# STM32MP25_CM33 register map
File version: 1.3
CPU: CM33 r0p1, little endian, MPU, FPU, vendor SysTick, 8 interrupt priority bits
Registers are 32-bit, read-write, reset 0x0 unless marked. A register's access mark holds for its fields unless they carry their own. Offsets are from the block's base; [hi:lo] are bit positions; {n}, {i} and the like mark numbered series.

## CRYP1 — CRYP address block description
Base 0x42030000
Same registers: CRYP2 0x42040000, CRYP1_S 0x52030000, CRYP2_S 0x52040000
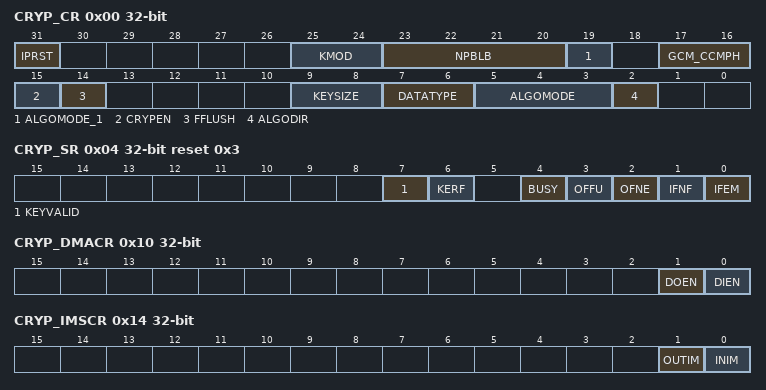
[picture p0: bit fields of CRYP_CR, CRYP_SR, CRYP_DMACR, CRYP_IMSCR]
0x00 CRYP_CR — CRYP control register
  [31] IPRST — CRYP peripheral software reset Setting the bit resets the CRYP peripheral, putting all registers to their default values, except the IPRST bit itself. This bit must be kept cleared while writing any configuration registers.
  [25:24] KMOD — Key mode selection This bit field defines how the CRYP key can be used by the application. KEYSIZE must be correctly initialized when setting KMOD[1:0] different from zero. Others: Reserved Shared-key mode can only be used in AES mode. Attempts to write the bit field are ignored when BUSY is set.
    0=Normal-key mode. Key registers are freely usable.; 2=Shared-key mode. If shared-key mode is properly initialized in SAES peripheral, the CRYP peripheral automatically loads its key registers with the data stored in the SAES key registers. The key value is available in CRYP key registers when BUSY bit is cleared and KEYVALID is set in the CRYP_SR register. Key error flag KERF is set otherwise in the CRYP_SR register.
  [23:20] NPBLB — Number of padding bytes in last block This padding information must be filled by software before processing the last block of GCM payload encryption or CCM payload decryption, otherwise authentication tag computation is incorrect. ... Attempts to write the bit field are ignored when BUSY is set.
    0=All bytes are valid (no padding); 1=Padding for the last LSB byte; 15=Padding for the 15 LSB bytes of last block
  [19] ALGOMODE_1 — ALGOMODE[3]
  [17:16] GCM_CCMPH — GCM or CCM phase selection This bit field selects the phase, applicable only with GCM, GMAC or CCM chaining modes. Attempts to write the bit field are ignored when BUSY is set.
    0=Initialization phase; 1=Header phase; 2=Payload phase; 3=Final phase
  [15] CRYPEN — CRYP enable This bit enables/disables the CRYP peripheral. This bit is automatically cleared by hardware upon the completion of the key preparation (ALGOMODE[3:0] at 0x7) and upon the completion of GCM/GMAC/CCM initialization phase. The bit cannot be set as long as KEYVALID is cleared.
    0=CRYP disabled; 1=CRYP enabled
  [14] FFLUSH — FIFO flush This bit enables/disables the flushing of CRYP input and output FIFOs. Reading this bit always returns 0. When CRYPEN is cleared, writing this bit to 1 flushes both input and output FIFOs (that is read and write pointers of the FIFOs are reset). FFLUSH bit must be set when BUSY is cleared, otherwise the FIFO is flushed, but the block being processed may be pushed into the output FIFO just after the flush operation, resulting in a non-empty FIFO condition. Attempts to write FFLUSH are ignored when CRYPEN is set.
    0=No effect; 1=FIFO flush enabled
  [9:8] KEYSIZE — Key size selection This bit field defines the key length in bits of the key used by CRYP in AES mode (that is, it has no effect in the DES or TDES modes). When KEYSIZE is changed, KEYVALID bit is cleared. Attempts to write the bit field are ignored when BUSY is set.
    0=128-bits; 1=192 bits; 2=256 bits
  [7:6] DATATYPE — Data type This bit field defines the format of data written in the CRYP_DINR register or read from the CRYP_DOUTR register, through selecting the mode of data swapping. This swapping is defined in Section59.4.16: CRYP data registers and data swapping. Attempts to write the bit field are ignored when BUSY is set.
    0=No swapping (32-bit data); 1=Half-word swapping (16-bit data); 2=Byte swapping (8-bit data); 3=Bit-level swapping
  [5:3] ALGOMODE — ALGOMODE[2:0]: Algorithm mode This bit field selects the algorithm/chaining mode. Others: Reserved Changing ALGOMODE[3:0] from AES algorithm to DES or TDES (or the reverse) clears KEYVALID. KEYVALID is not cleared when the algorithm type is kept between two ALGOMODE[3:0], that is between TDES-ECB and TDES-CBC or between AES-ECB and AES_CTR. Attempts to write the bit field are ignored when BUSY is set.
    0=TDES-ECB (triple-DES Electronic Codebook); 1=TDES-CBC (triple-DES Cipher Block Chaining); 2=DES-ECB (simple DES Electronic Codebook); 3=DES-CBC (simple DES Cipher Block Chaining); 4=AES electronic codebook (AES-ECB); 5=AES cipher Block Chaining (AES-CBC); 6=AES counter mode (AES-CTR); 7=AES key preparation for ECB or CBC decryption
  [2] ALGODIR — Algorithm direction This bit selects the algorithm direction. Attempts to write the bit field are ignored when BUSY is set.
    0=Encryption; 1=Decryption
0x04 CRYP_SR ro reset 0x3 — CRYP status register
  [7] KEYVALID — Key valid flag This read-only bit is set by hardware when the key of size defined by KEYSIZE is loaded in CRYP_KxR/LR key registers. It is valid for both AES and DES/TDES algorithms. The CRYPEN bit can only be set when KEYVALID is set. In normal mode when KMOD[1:0] is at zero, the key must be written in the key registers in the correct sequence, otherwise the KERF flag is set and KEYVALID remains cleared. When KMOD[1:0] is different from zero, the BUSY flag is automatically set by CRYP. When the key is loaded successfully, BUSY is cleared and KEYVALID set. Upon an error, KERF is set, BUSY cleared and KEYVALID remains cleared. If set, KERF must be cleared, otherwise KEYVALID cannot be set. For further information on key loading, refer to Section59.4.17: CRYP key registers.
    0=Key not valid; 1=Key valid
  [6] KERF — Key error flag This read-only bit is set by hardware when key information failed to load into key registers. KERF is triggered upon any of the following errors: CRYP_KxR/LR register write does not respect the correct order (refer to Section59.4.17: CRYP key registers for details). CRYP fails to load the AES key shared by SAES peripheral (KMOD=0x2). Application wrote KMOD=0x2 with ALGOMODE[3:0] selecting either DES or TDES algorithm. KERF must be cleared by the application software, otherwise KEYVALID cannot be set. It can be done through IPRST bit of CRYP_CR, or when a correct key writing sequence starts.
    0=No key error detected; 1=Key information failed to load into key registers
  [4] BUSY — Busy bit This flag indicates whether CRYP is idle or busy. CRYP is flagged as idle when disabled (CRYPEN=0) or when the AES or DES core is not processing any data. It happens when the last processing has completed, or CRYP is waiting for enough data in the input FIFO or enough free space in the output FIFO (that is in each case at least 2 words in the DES, 4 words in the AES). CRYP is flagged as busy when processing a block data, preparing a key (AES ECB or CBC decryption only), or transferring a shared key from SAES peripheral.
    0=Idle; 1=Busy
  [3] OFFU — Output FIFO full flag
    0=Output FIFO is not full; 1=Output FIFO is full
  [2] OFNE — Output FIFO not empty flag
    0=Output FIFO is empty; 1=Output FIFO is not empty
  [1] IFNF — Input FIFO not full flag
    0=Input FIFO is full; 1=Input FIFO is not full
  [0] IFEM — Input FIFO empty flag
    0=Input FIFO is not empty; 1=Input FIFO is empty
0x08 CRYP_DINR — CRYP data input register
  [31:0] DIN — Data input In AES mode four-fold sequential write to this bit field during the Input phase results in pushing a complete 16-byte block into the CRYP input FIFO. From the first to the fourth write, the corresponding data weights are [127:96], [95:64], [63:32], and [31:0]. In DES/TDES mode a two-fold sequential write to this bit field during the Input phase results in pushing a complete 8-bytes block into the CRYP input FIFO. From the first to the second write, the corresponding data weights are [63:32] then [31:0]. Input FIFO can receive up to two 16-byte blocks of plaintext (when encrypting) or ciphertext (when decrypting) in AES mode. In DES/TDES mode it is up to four 8-byte blocks. If EN bit is set in CRYP_CR register, when at least four 32-bit words have been pushed into the input FIFO (two in DES/TDES mode), and when at least four 32-bit words are free in the output FIFO (two in DES/TDES mode), the CRYP automatically starts an encryption or decryption process, setting the BUSY bit. Reading this register pops data off the input FIFO (oldest value is returned). The data present in the input FIFO are returned only if CRYPENis cleared (undefined value is returned otherwise). Following one or more reads the FIFO must be flushed (setting the FFLUSH bit) prior to processing new data.
0x0C CRYP_DOUTR ro — CRYP data output register
  [31:0] DOUT — Data output In AES mode four-fold sequential read to this bit field during the output phase results in retrieving a complete 16-byte block from the CRYP output FIFO. From the first to the fourth read, the corresponding data weights are [127:96], [95:64], [63:32], and [31:0]. In DES/TDES mode a two-fold sequential read to this bit field during the output phase results in retrieving a complete 8-byte block from the CRYP input FIFO. From the first to the second read, the corresponding data weights are [63:32] then [31:0]. Output FIFO can store up to two 16-byte blocks of plaintext (when decrypting) or ciphertext (when encrypting) in AES mode. In DES/TDES mode it is up to four 8-byte blocks. When the output FIFO is empty a read returns an undefined value. Writes are ignored.
0x10 CRYP_DMACR — CRYP DMA control register
  [1] DOEN — DMA output enable When this bit is set, DMA requests are automatically generated by the peripheral during the output data phase.
    0=Outgoing data transfer from CRYP via DMA is disabled; 1=Outgoing data transfer from CRYP via DMA is enabled
  [0] DIEN — DMA input enable When this bit is set, DMA requests are automatically generated by the peripheral during the input data phase.
    0=Incoming data transfer to CRYP via DMA is disabled; 1=Incoming data transfer to CRYP via DMA is enabled
0x14 CRYP_IMSCR — CRYP interrupt mask set/clear register
  [1] OUTIM — Output FIFO service interrupt mask This bit enables or disables (masks) the CRYP output FIFO service interrupt generation when OUTRIS is set.
    0=Output FIFO interrupt is disabled (masked), masked interrupt status (OUTMIS) stays cleared; 1=Output FIFO interrupt is enabled (not masked)
  [0] INIM — Input FIFO service interrupt mask This bit enables or disables (masks) the CRYP input FIFO service interrupt generation when INRIS is set.
    0=Input FIFO interrupt is disabled (masked), masked interrupt status (INMIS) stays cleared; 1=Input FIFO interrupt is enabled (not masked)
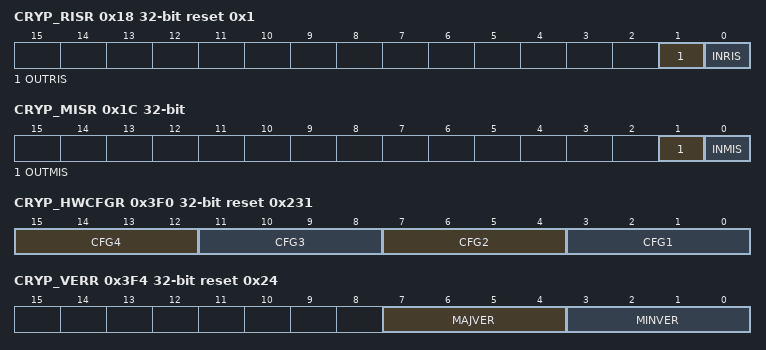
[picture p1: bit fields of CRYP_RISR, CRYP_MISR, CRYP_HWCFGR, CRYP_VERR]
0x18 CRYP_RISR ro reset 0x1 — CRYP raw interrupt status register
  [1] OUTRIS — Output FIFO service raw interrupt status This read-only bit is set by hardware when an output FIFO flag (OFFU or OFNE) is set in CRYP_SR register, regardless of the OUTIM mask bit value in CRYP_IMSCR register.
    0=No output FIFO event detected; 1=Output FIFO full or not empty detected; an interrupt is generated if OUTIM bit is set in CRYP_IMSCR register
  [0] INRIS — Input FIFO service raw interrupt status This read-only bit is set by hardware when an input FIFO flag (IFNF or IFEM) is set in CRYP_SR register, regardless of the INIM mask bit value in CRYP_IMSCR register.
    0=No input FIFO event detected; 1=Input FIFO empty or not full detected; an interrupt is generated if CRYPEN is set and if INIM bit is set in CRYP_IMSCR register
0x1C CRYP_MISR ro — CRYP masked interrupt status register
  [1] OUTMIS — Output FIFO service masked interrupt status This read-only bit is set by hardware when an output FIFO flag (OFFU or OFNE) is set in CRYP_SR register. If the OUTIM mask bit is cleared in CRYP_IMSCR register, the OUTMIS bit stays cleared (masked). The OUTMIS bit is cleared by reading data from the output FIFO until OFNE flag is cleared (output FIFO empty). It is not cleared by disabling CRYP with CRYPEN bit.
    0=No output FIFO event detected or OUTIM mask cleared in CRYP_IMSCR; 1=Output FIFO full or not empty detected, with an interrupt pending
  [0] INMIS — Input FIFO service masked interrupt status This read-only bit is set by hardware when an input FIFO flag (IFNF or IFEM) is set in CRYP_SR register. If the INIM mask bit is cleared in CRYP_IMSCR register, the INMIS bit stays cleared (masked). The INMIS bit is cleared by writing data to the input FIFO until IFEM flag is cleared (there is at least one word in input FIFO), or by clearing CRYPEN, When CRYP is disabled, INMIS bit stays low even if the input FIFO is empty.
    0=No input FIFO event detected or INIM mask cleared in CRYP_IMSCR or CRYPEN bit cleared; 1=Input FIFO empty or not full detected, with an interrupt pending
0x20 CRYP_K0LR wo — CRYP key register 0L
  [31:0] K — Key bit x (x= 255 to 224) This write-only bit field contains the bits [255:224] of the AES encryption or decryption key, depending on the operating mode. This register is not used in DES/TDES mode. Write to CRYP_KxR/LR registers is ignored when CRYP is busy (BUSY bit set). When key is coming from the SAES peripheral (KMOD[1:0]=0x2) in AES mode, write is also ignored. With KMOD[1:0] at 0x0, a special writing sequence is required. In this sequence, any valid write to CRYP_KxR/LR register clears the KEYVALID flag except for the sequence-completing write that sets it. Also refer to the description of the KEYVALID flag in the CRYP_SR register.
0x24 CRYP_K0RR wo — CRYP key register 0R
  [31:0] K — Key bit x (x= 223 to 192) This write-only bit field contains the bits [223:192] of the AES encryption or decryption key, depending on the operating mode. This register is not used in DES/TDES mode. Refer to the CRYP_K0LR register for information relative to writing CRYP_KxR/LR registers.
0x28 CRYP_K1LR wo — CRYP key register 1L
  [31:0] K — Key bit x (x= 191 to 160) This write-only bit field contains the bits [191:160] of the AES encryption or decryption key, depending on the operating mode. In DES/TDES mode this bit field contains the bits [64:33] of the key K1, with parity bits unused. Refer to the CRYP_K0LR register for information relative to writing CRYP_KxR/LR registers.
0x2C CRYP_K1RR wo — CRYP key register 1R
  [31:0] K — Key bit x (x= 159 to 128) This write-only bit field contains the bits [159:128] of the AES encryption or decryption key, depending on the operating mode. In DES/TDES mode this bit field contains the bits [32:1] of the key K1, with parity bits unused. Refer to the CRYP_K0LR register for information relative to writing CRYP_KxR/LR registers.
0x30 CRYP_K2LR wo — CRYP key register 2L
  [31:0] K — Key bit x (x= 127 to 96) This write-only bit field contains the bits [127:96] of the AES encryption or decryption key, depending on the operating mode. In DES/TDES mode this bit field contains the bits [64:33] of the key K2, with parity bits unused. Refer to the CRYP_K0LR register for information relative to writing CRYP_KxR/LR registers.
0x34 CRYP_K2RR wo — CRYP key register 2R
  [31:0] K — Key bit x (x= 95 to 64) This write-only bit field contains the bits [95:64] of the AES encryption or decryption key, depending on the operating mode. In DES/TDES mode this bit field contains the bits [32:1] of the key K2, with parity bits unused. Refer to the CRYP_K0LR register for information relative to writing CRYP_KxR/LR registers.
0x38 CRYP_K3LR wo — CRYP key register 3L
  [31:0] K — Key bit x (x= 63 to 32) This write-only bit field contains the bits [63:32] of the AES encryption or decryption key, depending on the operating mode. In DES/TDES mode this bit field contains the bits [64:33] of the key K3, with parity bits unused. Refer to the CRYP_K0LR register for information relative to writing CRYP_KxR/LR registers.
0x3C CRYP_K3RR wo — CRYP key register 3R
  [31:0] K — Key bit x (x= 31 to 0) This write-only bit field contains the bits [31:0] of the AES encryption or decryption key, depending on the operating mode. In DES/TDES mode this bit field contains the bits [32:1] of the key K3, with parity bits unused. Refer to the CRYP_K0LR register for information relative to writing CRYP_KxR/LR registers.
0x40 CRYP_IV0LR — CRYP initialization vector register 0L
  [31:0] IVI — Initialization vector bit x (x= 127 to 96) This bit field stores the initialization vector bits [127:96] for AES chaining modes other than ECB. In DES/TDES mode it corresponds to IVI bits [63:32]. The value stored in CRYP_IVxR/LR registers is updated by hardware after each computation round (when applicable). Write to this register is ignored when CRYP is busy (BUSY bit set).
0x44 CRYP_IV0RR — CRYP initialization vector register 0R
  [31:0] IVI — Initialization vector bit x (x= 95 to 64) This bit field stores the initialization vector bits [95:64] for AES chaining modes other than ECB. In DES/TDES mode it corresponds to IVI bits [31:0]. The value stored in CRYP_IVxR/LR registers is updated by hardware after each computation round (when applicable). Write to this register is ignored when CRYP is busy (BUSY bit set).
0x48 CRYP_IV1LR — CRYP initialization vector register 1L
  [31:0] IVI — Initialization vector bit x (x= 63 to 32) This bit field stores the initialization vector bits [63:32] for AES chaining modes other than ECB. This register is not used in DES/TDES mode. The value stored in CRYP_IVxR/LR registers is updated by hardware after each computation round (when applicable). Write to this register is ignored when CRYP is busy (BUSY bit set).
0x4C CRYP_IV1RR — CRYP initialization vector register 1R
  [31:0] IVI — Initialization vector bit x (x= 31 to 0) This bit field stores the initialization vector bits [31:0] for AES chaining modes other than ECB. This register is not used in DES/TDES mode. The value stored in CRYP_IVxR/LR registers is updated by hardware after each computation round (when applicable). Write to this register is ignored when CRYP is busy (BUSY bit set).
{0x50+4i} CRYP_CSGCMCCM{i}R (i=0..7) — CRYP context swap GCM-CCM registers
  [31:0] CSGCMCCM — Context swap for GCM/GMAC and CCM modes CRYP_CSGCMCCMxR registers contain the complete internal register states of the CRYP when the GCM, GMAC or CCM processing of the current task is suspended to process a higher-priority task. Refer to Section59.4.8: CRYP suspend and resume operations for more details. CRYP_CSGCMCCMxR registers are not used in DES/TDES or other AES chaining modes than GCM, GMAC or CCM.
{0x70+4i} CRYP_CSGCM{i}R (i=0..7) — CRYP context swap GCM registers
  [31:0] CSGCM — Context swap for GCM/GMAC modes CRYP_CSGCMxR registers contain the complete internal register states of the CRYP when the GCM or GMAC processing of the current task is suspended to process a higher-priority task. Refer to Section59.4.8: CRYP suspend and resume operations for more details. CRYP_CSGCMxR registers are not used in DES/TDES or other AES chaining modes than GCM or GMAC.
0x3F0 CRYP_HWCFGR ro reset 0x231 — CRYP hardware configuration register
  [15:12] CFG4 — Hardware Generic 4 Reserved, must be kept at reset value.
  [11:8] CFG3 — Hardware Generic 3 This field returns the dma_version generic value (0x2).
  [7:4] CFG2 — Hardware Generic 2 This field returns the aes_impl generic value (0x3).
  [3:0] CFG1 — Hardware Generic 1 This field returns the tdes_impl generic value (0x1).
0x3F4 CRYP_VERR ro reset 0x24 — CRYP version register
  [7:4] MAJVER — CRYP processor major version This field returns the CRYP processor major version.
  [3:0] MINVER — CRYP processor minor version This field returns the CRYP processor minor version.
0x3F8 CRYP_IPIDR ro reset 0x170011 — CRYP identification
  [31:0] ID — Identification code This field returns the identification code of the CRYP processor.
0x3FC CRYP_SIDR ro reset 0xA3C5DD01 — CRYP size identification register
  [31:0] SID — Size identification code This field returns the size identification code of the CRYP processor as defined below: SID[31:8]=0xA3C5DD (fixed code) SID[7:0]=0x01 (1-Kbyte address decoding)
